# PIC32MZ2051W104132 device description
Architecture: MIPS; Family: PIC32MZW; Series: PIC32MZW
Registers are 32-bit, read-write, no defined reset value unless marked. A register's access mark holds for its fields unless they carry their own. Offsets are from the block's base; [hi:lo] are bit positions; {n}, {i} and the like mark numbered series; 'fields as' and 'values as' point back to an identical list.

## CFG
Instances: CFG 0x1f800000 in configSfr0
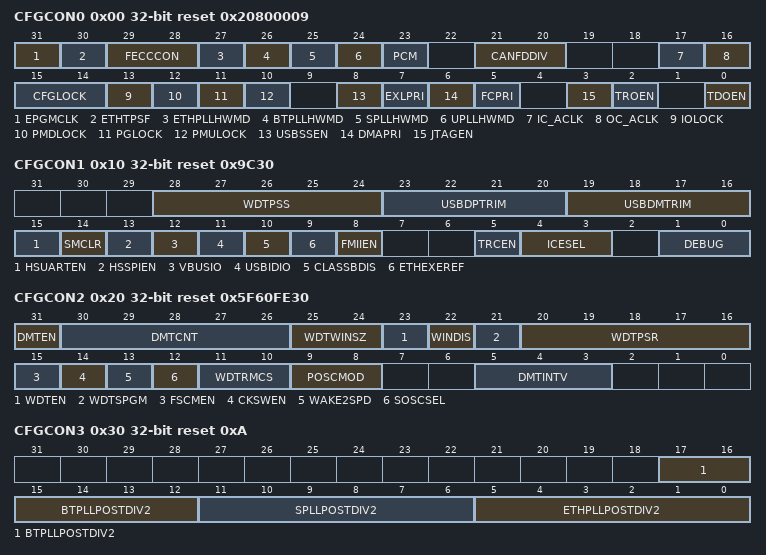
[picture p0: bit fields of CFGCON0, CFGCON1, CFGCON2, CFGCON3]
0x00 CFGCON0 reset 0x20800009
  [31] EPGMCLK — External Programming Clock enable
    1=TSTFRC (In ICSP (TMOD0) mode, enable the FRC clock to be driven by the TSTFRC Pin Function); 0=FRC (In ICSP (TMOD0) mode, the FRC clock is always driven by the FRC oscillator)
  [30] ETHTPSF — Ethernet Tx SOF enabled for CTR measurements
    1=TPSF (TPSF is enabled in CTR measurement); 0=RPSF (RPSF is enabled in CTR measurement)
  [29:28] FECCCON — Flash ECC Control
    2=DISABLED (ECC and Dynamically ECC Disabled); 1=DYNAMIC (Dynamically ECC Enabled); 0=ECC (ECC Enabled (NVMOP = Word Programming disabled))
  [27] ETHPLLHWMD — EWPLL HW Control Mode for PWDN and RESET
    1=HW (PWDN and RESET are generated by HW); 0=SW (PWDN and RESET are generated by SW using corresponding PLLCON register bits)
  [26] BTPLLHWMD — BTPLL HW Control Mode for PWDN and RESET
    values as ETHPLLHWMD
  [25] SPLLHWMD — SPLL HW Control Mode for PWDN and RESET
    values as ETHPLLHWMD
  [24] UPLLHWMD — UPLL HW Control Mode for PWDN and RESET
    values as ETHPLLHWMD
  [23] PCM — PCHE I/D Cacheable Mode
    1=OUTSIDE (Always enabled from outside. Can be further enabled/disabled by PCHE SFR registers.); 0=HPROT (The cache-ability is controlled by the MIPS CPU via HPROT[3]. This feature is not available on all the MIPS cores.)
  [21:20] CANFDDIV — CAN-FD Back-up Clock Divider
    0=DIV2 (Divide-by 2); 2=DIV4 (Divide-by 4); 3=DIV8 (Divide-by 8)
  [17] IC_ACLK — ICAP Alternate Clock Selection
    1=OTHER (ICAP Modules use an alternative TMR pair as their timebase clock); 0=TMR (All ICAP Modules use TMR2/TMR3 as their timebase clock)
  [16] OC_ACLK — OCMP Alternate Clock Selection
    1=OTHER (OCMP Modules use an alternative TMR pair as their timebase clock); 0=TMR (All OCMP Modules use TMR2/TMR3 as their timebase clock)
  [15:14] CFGLOCK — Configuration Register Lock
    3=ALL_LOCKED (All NVR memory self-writes, Boot Configuration (BCFG0) and System Configuration registers (CFG* and USER_ID) are locked and can not be written - CFGLOCK value can not be changed); 2=LOCKED (All NVR memory self-writes, Boot Configuration (BCFG0) and System Configuration registers (CFG* and USER_ID) are locked and can not be written - CFGLOCK value can be changed.); 0=UNLOCKED (All NVR memory self-writes, Boot Configuration (BCFG0) and System Configuration registers (CFG* and USER_ID) are not locked and can be written - CFGLOCK value can be changed)
  [13] IOLOCK
    1=LOCKED (IO Remap SFR bits are locked and cannot be modified); 0=UNLOCKED (IO Remap SFR are not locked and can be modified)
  [12] PMDLOCK — Peripheral Module Disable (PMD) LOCK
    1=LOCKED (PMDx SFR bits are locked and cannot be modified); 0=UNLOCKED (PMDx SFR bits are not locked and can be modified)
  [11] PGLOCK — Permission Group LOCK
    1=LOCKED (CFGPG SFR bits are locked and cannot be modified); 0=UNLOCKED (CFGPG SFR bits are not locked and can be modified)
  [10] PMULOCK — PMU Controller Register LOCK
    1=LOCKED (PMU SFR bits are locked and cannot be modified); 0=UNLOCKED (PMU SFR bits are not locked and can be modified)
  [8] USBSSEN — USB Suspend Sleep Enable
    1=OFF (USB FREF clock is shut down when suspend mode is active.); 0=ON (USB FREF clock continues to run when suspend mode is active.)
  [7] EXLPRI — CPU arbitration Priority to SRAM when servicing an Interrupt
    1=SRAM (CPU gets High Priority access to SRAM1, SRAM2); 0=OTHER (CPU uses Least Recently Serviced Arbitration (same as other initiators))
  [6] DMAPRI — DMAR and DMAW arbitration Priority to SRAM
    1=SRAM (DMA gets High Priority access to SRAM1, SRAM2); 0=OTHER (DMA uses Least Recently Serviced Arbitration (same as other initiators))
  [5] FCPRI — FC arbitration Priority to SRAM
    1=SRAM (FC gets High Priority access to SRAM1, SRAM2); 0=OTHER (FC uses Least Recently Serviced Arbitration (same as other initiators))
  [3] JTAGEN — JTAG control bit
    1=ENABLE (JTAG Port Enabled); 0=DISABLE (JTAG Port Disabled)
  [2] TROEN — Trace clock control bit
    1=ENABLE (Start Trace Clock and enable Trace Outputs (Trace Probe must be present)); 0=DISABLE (Stop Trace Clock and disable Trace Outputs)
  [0] TDOEN — TDO control for 2 wire JTAG protocol
    1=TDO (2-wire JTAG protocol uses TDO (Four phase (Full Duplex) Protocol)); 0=NO_TDO (2-wire JTAG protocol does not use TDO (Two phase (Half Duplex) Protocol))
0x10 CFGCON1 reset 0x9C30 — CONFIGURATION CONTROL REGISTER 1
  [28:24] WDTPSS — Watchdog Timer Post-scale Select Sleep bits
    20=DIV_1048576 (1:1048576); 19=DIV_524288 (1:524288); 18=DIV_262144 (1:262144); 17=DIV_131072 (1:131072); 16=DIV_65536 (1:65536); 15=DIV_32768 (1:32768); 14=DIV_16384 (1:16384); 13=DIV_8192 (1:8192); 12=DIV_4096 (1:4096); 11=DIV_2048 (1:2048); 10=DIV_1024 (1:1024); 9=DIV_512 (1:512); 8=DIV_256 (1:256); 7=DIV_128 (1:128); 6=DIV_64 (1:64); 5=DIV_32 (1:32); 4=DIV_16 (1:16); 3=DIV_8 (1:8); 2=DIV_4 (1:4); 1=DIV_2 (1:2); 0=DIV_1 (1:1)
  [23:20] USBDPTRIM — USB DM Rise/Fall Trim fuse bits
  [19:16] USBDMTRIM — USB DP Rise/Fall Trim fuse bits
  [15] HSUARTEN — UART1 High Speed Mode Enable
    1=DEDICATED_PINS (UART1 is driven from/to dedicated pins resulting in the highest possible maximum baud rate); 0=PPS_PINS (UART1 is driven through PPS (I/O remap) resulting in a lower maximum baud rate)
  [14] SMCLR — Selects CRU handling of MCLR Control
    1=MCLR_NORM (Legacy mode (system clear does not reset all state of device)); 0=MCLR_POR (MCLR causes a faux POR)
  [13] HSSPIEN — High Speed Mode Enable (SPI-1)
    1=DEDICATED_PINS (SPI1 is driven from/to dedicated pins resulting in the highest interface speed); 0=PPS_PINS (SPI1 is driven through PPS (I/O remap) resulting in a lower interface speed)
  [12] VBUSIO — USB VBUS_ON Selection bit
    1=USB (VBUS_ON pin is controlled by the USB Module); 0=PORT (VBUS_ON pin is controlled by the Port Function)
  [11] USBIDIO — USB USBID Selection bit
    1=USB (USBID pin is controlled by the USB Module); 0=PORT (USBID pin is controlled by the Port Function)
  [10] CLASSBDIS — Disable CLASSB Device Functionality
    0=ENABLED (CLASSB functions enabled); 1=DISABLED (CLASSB functions disabled)
  [9] ETHEXEREF — Exclusive Ethernet PYHY reference clock Enable
    0=ETH_CLK_OUT (ETH_CLK_OUT will be used as PHY reference clock if needed (Refer IOM)); 1=PHY (PHY reference clock is made available on ETH_EXCLK_OUT (Refer IOM))
  [8] FMIIEN — Ethernet1 MII Enable
    1=18PIN (18-pin 25MHz Media Independent Interface is enabled); 0=10PIN (10-pin 50MHz Reduced Media Independent Interface is enabled)
  [5] TRCEN — Trace Enable
    1=ENABLED (Trace features in the CPU are enabled); 0=DISABLED (Trace features in the CPU are disabled)
  [4:3] ICESEL — EMUC/EMUD Communication Channel Select
    3=EMUx1_PGx1 (ICE EMUC1/EMUD1 pins are shared with PGC1/PGD1); 2=EMUx2_PGx2 (ICE EMUC2/EMUD2 pins are shared with PGC2/PGD2); 1=EMUx3_PGx3 (ICE EMUC3/EMUD3 pins are shared with PGC3/PGD3 (Not used on this device)); 0=EMUx4_PGx4 (ICE EMUC4/EMUD4 pins are shared with PGC4/PGD4)
  [1:0] DEBUG — Background Debugger Access Selection
    3=JTAGEN_EMUDIS_ICDDIS (4-wire JTAG I/F Enabled - EMUC/EMUD Disabled - ICD Module Disabled); 2=JTAGEN_EMUDIS_ICDEN (4-wire JTAG I/F Enabled - EMUC/EMUD Disabled - ICD Module Enabled); 1=JTAGDIS_EMUEN_ICDDIS (EMUC/EMUD Enabled - 4-wire JTAG I/F Disabled - ICD Module Disabled); 0=JTAGDIS_EMUEN_ICDEN (EMUC/EMUD Enabled - 4-wire JTAG I/F Disabled - ICD Module Enabled)
0x20 CFGCON2 reset 0x5F60FE30 — CONFIGURATION CONTROL REGISTER 2
  [31] DMTEN — Dead Man Timer Enable bit
    1=ENABLED (DMT enabled); 0=DISABLED (DMT disabled (control is placed on the DMTCON.ON bit))
  [30:26] DMTCNT — Dead Man Timer Count Select bits
    {v}=2^{v+8} (Counter value is 2^{v+8} for cfg_dmt_cnt[31-0]) (v=0..23)
  [25:24] WDTWINSZ — Watchdog Timer Window Size bits
    0=75_PERCENT (Window size is 75%); 1=50_PERCENT (Window size is 50%); 2=37.5_PERCENT (Window size is 37.5%); 3=25_PERCENT (Window size is 25%)
  [23] WDTEN — Watchdog Timer Enable bit
    1=ENABLED (WDT enabled); 0=DISABLED (WDT disabled (control is placed on the SWDTEN bit))
  [22] WINDIS — Windowed Watchdog Timer Disable bit
    1=STANDARD (Standard WDT selected; windowed WDT disabled); 0=WINDOWED (Windowed WDT enabled)
  [21] WDTSPGM — Watchdog Timer Stop during Flash Programming bit
    1=STOP (The WDT stops during NVR programming (legacy)); 0=RUN (The WDT runs during NVR programming (for read/execute while programming flash systems))
  [20:16] WDTPSR — Watchdog Timer Post-scale Select Run bits
    values as CFGCON1.WDTPSS
  [15] FSCMEN — Fail-Safe Clock Monitor Enable
    1=ENABLED (FSCM Enabled); 0=DISABLED (FSCM Disabled)
  [14] CKSWEN — Software Clock Switching Enable
    1=ENABLED (Software Clock Switching Enabled); 0=DISABLED (Software Clock Switching Disabled)
  [13] WAKE2SPD — 2-Speed startup enabled in Sleep mode bit
    1=FRC (When the device EXITS Sleep Mode, the sys_clk will be from FRC until the selected clock is ready); 0=SELECTED_CLK (When the device EXITS Sleep Mode, the sys_clk will be from the selected clock.)
  [12] SOSCSEL — SOSC Selection Configuration bit
    1=SOSCx (Crystal (SOSCI/SOSCO) mode); 0=SCLKI (Digital (SCLKI) mode)
  [11:10] WDTRMCS — WDT RUN Mode Clock Select
    3=LPRC; 0=PB_CLK (Module PB Clock)
  [9:8] POSCMOD — Primary Oscillator Configuration bits
    3=PRI_DISABLED (Primary oscillator disabled); 2=HS_OSC (HS oscillator mode selected)
  [5:3] DMTINTV — Dead Man Timer Count Window Interval bits
    0=DIV1 (Window/Interval value is Counter value for cfg_dmt_intv[31-0]); 1=DIV2 (Window/Interval value is 1/2 Counter value for cfg_dmt_intv[31-0]); 2=DIV4 (Window/Interval value is 1/4 Counter value for cfg_dmt_intv[31-0]); 3=DIV8 (Window/Interval value is 1/8 Counter value for cfg_dmt_intv[31-0]); 4=DIV16 (Window/Interval value is 1/16 Counter value for cfg_dmt_intv[31-0]); 5=DIV32 (Window/Interval value is 1/32 Counter value for cfg_dmt_intv[31-0]); 6=DIV64 (Window/Interval value is 1/64 Counter value for cfg_dmt_intv[31-0]); 7=DIV128 (Window/Interval value is 1/128 Counter value for cfg_dmt_intv[31-0])
0x30 CFGCON3 reset 0xA — CONFIGURATION CONTROL REGISTER 3
  [all] fields
    {v}=DIV{v} (Divide by {v}) (v=1..63)
  [17:12] BTPLLPOSTDIV2 — BTPLL Post Divider bits for controlling auxiliary second PLL clock output.
  [11:6] SPLLPOSTDIV2 — SPLL Post Divider bits for controlling auxiliary second PLL clock output.
  [5:0] ETHPLLPOSTDIV2 — EWPLL Post Divider bits for controlling second PLL clock output for WiFI
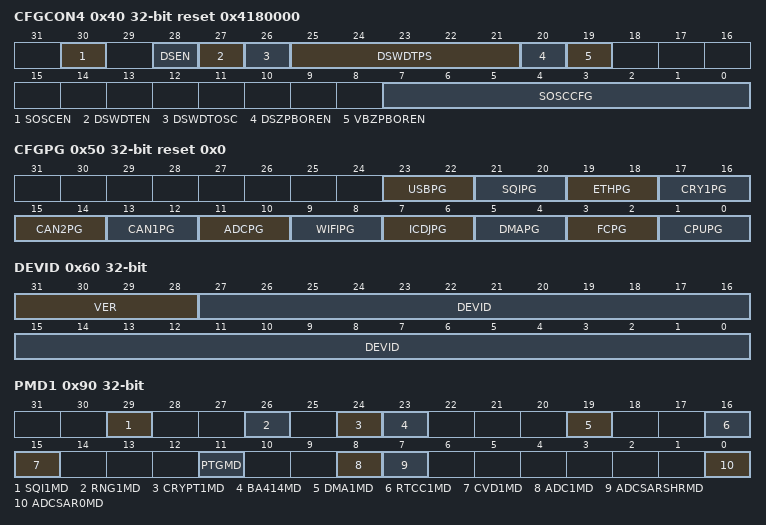
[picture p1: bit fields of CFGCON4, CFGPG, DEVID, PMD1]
0x40 CFGCON4 reset 0x4180000 — CONFIGURATION CONTROL REGISTER 4
  [30] SOSCEN — Low Power (Secondary) Oscillator Enable bit
    1=ENABLE (Enable Low Power (Secondary) Oscillator - also at reset); 0=DISABLE (Disable Low Power (Secondary) Oscillator)
  [28] DSEN — Deep Sleep Bit Enable bit
    0=DISABLE (Disable DSEN Bit in DSCON); 1=ENABLE (Enable DSEN Bit in DSCON)
  [27] DSWDTEN — Deep Sleep Watchdog Timer Enable bit
    0=DISABLE (Disable DSWDT during Deep Sleep); 1=ENABLE (Enable DSWDT during Deep Sleep)
  [26] DSWDTOSC — Deep Sleep Watchdog Timer Reference Clock Select bit
    0=SOSC (Select SOSC as DSWDT reference clock); 1=LPRC (Select LPRC as DSWDT reference clock)
  [25:21] DSWDTPS — Deep Sleep Watchdog Timer Postscale Select bits
    31=25DAYS (1:236 (25.7 days)); 30=12DAYS (1:235 (12.8 days)); 29=6DAYS (1:234 (6.4 days)); 28=77HRS (1:233 (77.0 hours)); 27=38HRS (1:232 (38.5 hours)); 26=19HRS (1:231 (19.2 hours)); 25=9HRS (1:230 (9.6 hours)); 24=4HRS (1:229 (4.8 hours)); 23=2HRS (1:228 (2.4 hours)); 22=72MINS (1:227 (72.2 minutes)); 21=36MINS (1:226 (36.1 minutes)); 20=18MINS (1:225 (18.0 minutes)); 19=9MINS (1:224 (9.0 minutes)); 18=4MINS (1:223 (4.5 minutes)); 17=135SEC (1:222 (135.3 s)); 16=67SEC (1:221 (67.7 s)); 15=33SEC (1:220 (33.825 s)); 14=16SEC (1:219 (16.912 s)); 13=8SEC (1:218 (8.456 s)); 12=4SEC (1:217 (4.228 s)); 11=2SEC (1:65536 (2.114 s)); 10=1SEC (1:32768 (1.057 s)); 9=528MSEC (1:16384 (528.5 ms)); 8=264MSEC (1:8192 (264.3 ms)); 7=132MSEC (1:4096 (132.1 ms)); 6=66MSEC (1:2048 (66.1 ms)); 5=33MSEC (1:1024 (33 ms)); 4=16MSEC (1:512 (16.5 ms)); 3=8MSEC (1:256 (8.3 ms)); 2=4MSEC (1:128 (4.1 ms)); 1=2MSEC (1:64 (2.1 ms)); 0=1MSEC (1:32 (1 ms))
  [20] DSZPBOREN — Deep Sleep Zero-Power BOR Enable bit
    0=DISABLE (Disable ZPBOR during deep sleep); 1=ENABLE (Enable ZPBOR during deep sleep)
  [19] VBZPBOREN — VBAT Zero-Power BOR Enable bit
    0=DISABLE (Disable ZPBOR during VBAT mode); 1=ENABLE (Enable ZPBOR during VBAT mode)
  [7:0] SOSCCFG — SOSC Configuration Bits
0x50 CFGPG reset 0x0 — PERMISSION GROUP CONFIGURATION REGISTER
  [all] fields
    {v}=GROUP{v} (Read Access if RDPER[{v}] is 1- Write Access if WRPER[{v}] is 1 (Perm. Grp. {v})) (v=0..3)
  [23:22] USBPG — USB Permission Group- drive directly the inputs cfg_usb_pg[1-0] to the SSX
  [21:20] SQIPG — SQI Permission Group- drive directly the inputs cfg_sqi_pg[1-0] to the SSX
  [19:18] ETHPG — ETH Permission Group
  [17:16] CRY1PG — CRY1 Permission Group
  [15:14] CAN2PG — CAN2 Permission Group
  [13:12] CAN1PG — CAN1 Permission Group
  [11:10] ADCPG — ADC Permission Group
  [9:8] WIFIPG — WIFI Permission Group
  [7:6] ICDJPG — ICD-JTAG Permission Group
  [5:4] DMAPG — DMA Permission Group
  [3:2] FCPG — FC Permission Group
  [1:0] CPUPG — CPU (Code) Permission Group
0x60 DEVID ro
  [31:28] VER, [27:0] DEVID
0x70 USERID — USER UNIQUE ID REGISTER
  [15:0] USERID
0x80 SYSKEY — SYSTEM KEY REGISTER
0x90 PMD1 — PERIPHERAL MODULE DISABLE 1 REGISTER
  [29] SQI1MD — SQI Module Disable
    1=Disabled; 0=Enabled
  [26] RNG1MD — RNG1 Module Disable
    1=Disabled; 0=Enabled
  [24] CRYPT1MD — CRYPTO1 Module Disable
    1=Disabled; 0=Enabled
  [23] BA414MD — BA414E Module Disable
    1=Disabled; 0=Enabled
  [19] DMA1MD — DMA Controller Module Disable
    1=Disabled; 0=Enabled
  [16] RTCC1MD — RTCC Module Disable (Unused at top level- part of XDS controller SFR)
    1=Disabled; 0=Enabled
  [15] CVD1MD — CVD Module Disable
    1=Disabled; 0=Enabled
  [11] PTGMD — PTG Module Disable
    1=Disabled; 0=Enabled
  [8] ADC1MD — ADC Controller Module Disable
    1=Disabled; 0=Enabled
  [7] ADCSARSHRMD — Shared ADC SAR Core Module Disable bit
    1=Disabled - When disabled the corresponding ADC SAR SHARED will be disabled; 0=Enabled
  [0] ADCSAR0MD — ADC SAR Core 0 Module Disable bit
    1=Disabled - When disabled the corresponding ADC SAR will be disabled; 0=Enabled
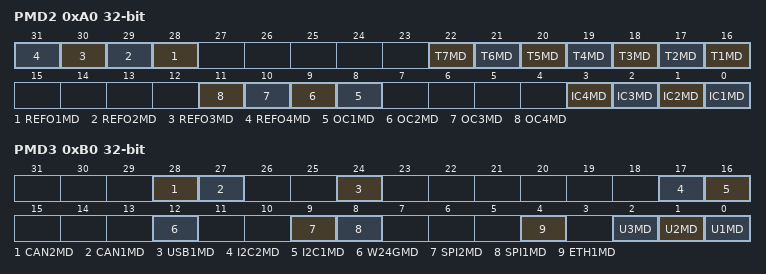
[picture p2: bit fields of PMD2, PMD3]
0xA0 PMD2 — PERIPHERAL MODULE DISABLE 2 REGISTER
  [all] fields
    1=Disabled; 0=Enabled
  [n+27] REFO{n}MD (n=1..4) — Reference (Clock) Out {n} Module Disable
  [n+15] T{n}MD (n=1..7) — Timer {n} Module Disable
  [n+7] OC{n}MD (n=1..4) — Output Compare {n} Module Disable bit
  [n-1] IC{n}MD (n=1..4) — Input Capture {n} Module Disable
0xB0 PMD3 — PERIPHERAL MODULE DISABLE 3 REGISTER
  [all] fields
    1=Disabled; 0=Enabled
  [28] CAN2MD — CAN Module Disable bit
  [27] CAN1MD — CAN Module Disable bit
  [24] USB1MD — USB Module Disable bit
  [17] I2C2MD — I2C 2 Module Disable
  [16] I2C1MD — I2C 1 Module Disable
  [12] W24GMD — WiFi Module Disable
  [9] SPI2MD — SPI 2 Module Disable
  [8] SPI1MD — SPI 1 Module Disable
  [4] ETH1MD — Ethernet Module Disable
  [2] U3MD — UART Module Disable
  [1] U2MD — UART Module Disable
  [0] U1MD — UART Module Disable
